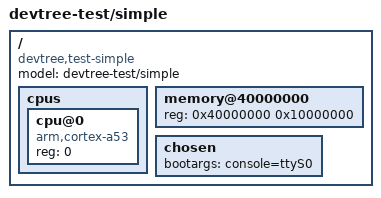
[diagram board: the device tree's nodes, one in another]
/dts-v1/;

/ {
	#address-cells = <1>;
	#size-cells = <1>;
	model = "devtree-test/simple";
	compatible = "devtree,test-simple";

	cpus {
		#address-cells = <1>;
		#size-cells = <0>;

		cpu@0 {
			device_type = "cpu";
			reg = <0>;
			compatible = "arm,cortex-a53";
		};
	};

	memory@40000000 {
		device_type = "memory";
		reg = <0x40000000 0x10000000>;
	};

	chosen {
		bootargs = "console=ttyS0";
	};
};
